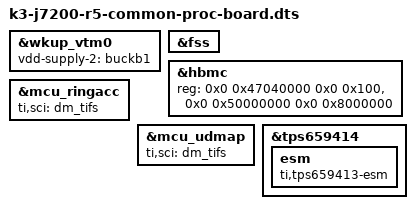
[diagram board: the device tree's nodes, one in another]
// SPDX-License-Identifier: GPL-2.0
/*
 * Copyright (C) 2020-2023 Texas Instruments Incorporated - https://www.ti.com/
 */

/dts-v1/;

#include "k3-j7200-common-proc-board.dts"
#include "k3-j7200-ddr-evm-lp4-2666.dtsi"
#include "k3-j721e-ddr.dtsi"
#include "k3-j7200-common-proc-board-u-boot.dtsi"
#include "k3-j7200-r5.dtsi"

&wkup_vtm0 {
	bootph-pre-ram;
};

&fss {
	/* enable ranges missing from the FSS node */
	ranges = <0x0 0x47000000 0x0 0x47000000 0x0 0x00068400>,
	         <0x0 0x50000000 0x0 0x50000000 0x0 0x08000000>;
};

&hbmc {
	reg = <0x0 0x47040000 0x0 0x100>,
		<0x0 0x50000000 0x0 0x8000000>;
	ranges = <0x0 0x0 0x0 0x50000000 0x4000000>,
		<0x1 0x0 0x0 0x54000000 0x800000>;
};

&mcu_ringacc {
    ti,sci = <&dm_tifs>;
};

&mcu_udmap {
    ti,sci = <&dm_tifs>;
};

&wkup_vtm0 {
	vdd-supply-2 = <&buckb1>;
	bootph-pre-ram;
};

&tps659414 {
	esm: esm {
		compatible = "ti,tps659413-esm";
		bootph-pre-ram;
	};
};
